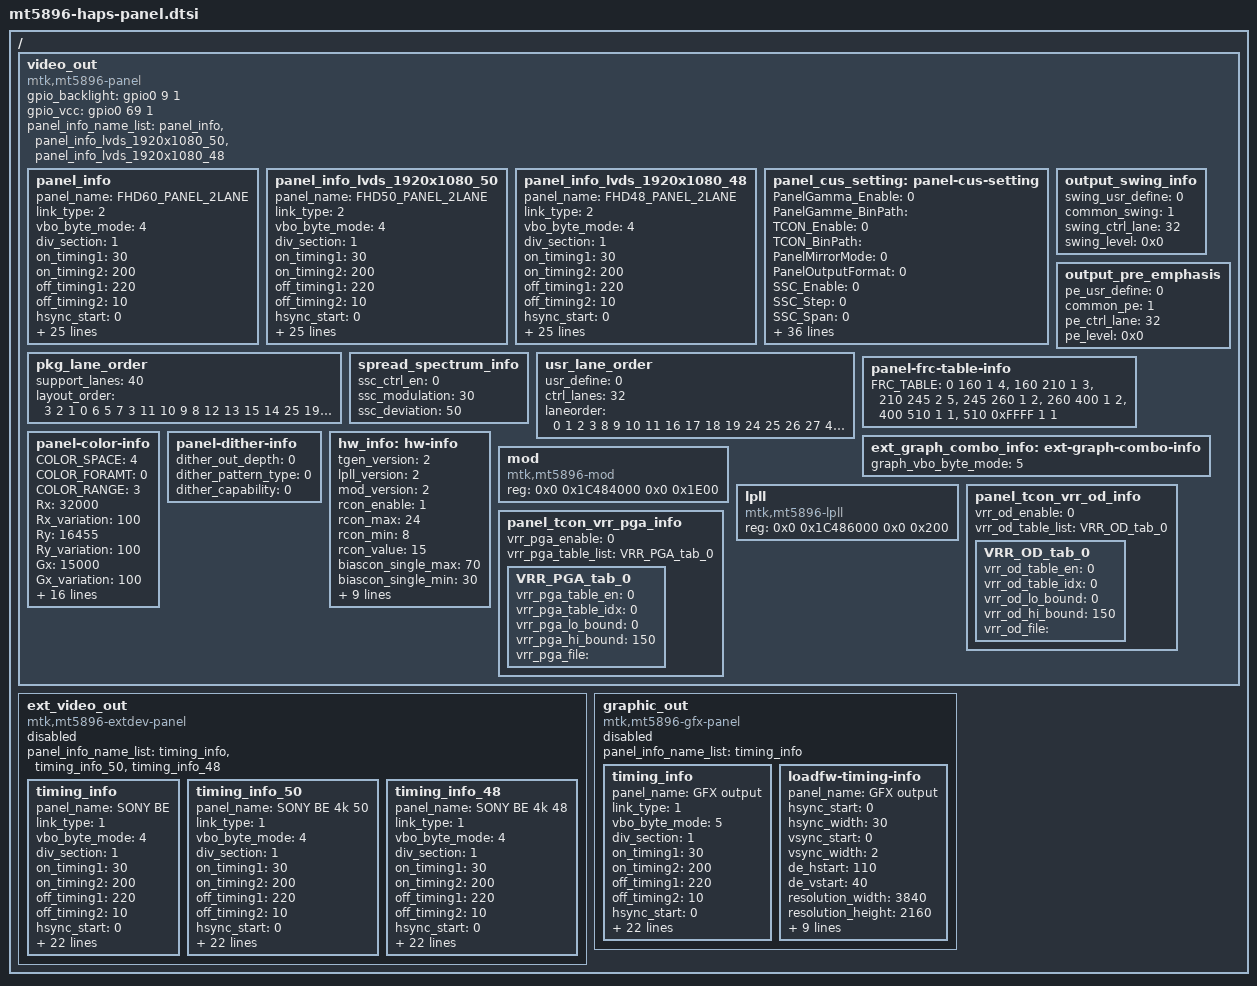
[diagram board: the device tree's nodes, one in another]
// SPDX-License-Identifier: (GPL-2.0 OR BSD-3-Clause)
/*
 * Copyright (c) 2020 MediaTek Inc.
 */

/{

	video_out:video_out {
		compatible = "mtk,mt5896-panel";
		status = "okay";
	#address-cells = <2>;
	#size-cells = <2>;
		gpio_backlight = <&gpio0 9 1>;
		gpio_vcc = <&gpio0 69 1>;
		panel_info_name_list = "panel_info", "panel_info_lvds_1920x1080_50",
		"panel_info_lvds_1920x1080_48";
		panel_info {
			panel_name = "FHD60_PANEL_2LANE";
			link_type = <2>;
			vbo_byte_mode = <4>;
			div_section = <1>;
			on_timing1 = <30>;
			on_timing2 = <200>;
			off_timing1 = <220>;
			off_timing2 = <10>;
			hsync_start = <0>;
			hsync_width = <30>;
			hsync_polarity = <1>;
			vsync_start = <0>;
			vsync_width = <2>;
			vsync_polarity = <1>;
			de_hstart = <110>;
			de_vstart = <98>;
			resolution_width = <1920>;
			resolution_height = <1080>;
			max_h_total = <2300>;
			typ_h_total = <2200>;
			min_h_total = <2100>;
			max_v_total = <1418>;
			typ_v_total = <1125>;
			min_v_total = <1078>;
			max_clk = <160000000>;
			typ_clk = <148500000>;
			min_clk = <140000000>;
			output_format = <0>;
			content_output_format = <0>;
			vrr_en = <0>;
			min_vrr_framerate = <30>;
			max_vrr_framerate = <120>;
			graphic_mixer1_outmode = <0>;
			graphic_mixer2_outmode = <1>;
		};
		panel_info_lvds_1920x1080_50 {
			panel_name = "FHD50_PANEL_2LANE";
			link_type = <2>;
			vbo_byte_mode = <4>;
			div_section = <1>;
			on_timing1 = <30>;
			on_timing2 = <200>;
			off_timing1 = <220>;
			off_timing2 = <10>;
			hsync_start = <0>;
			hsync_width = <30>;
			hsync_polarity = <1>;
			vsync_start = <0>;
			vsync_width = <2>;
			vsync_polarity = <1>;
			de_hstart = <110>;
			de_vstart = <98>;
			resolution_width = <1920>;
			resolution_height = <1080>;
			max_h_total = <2300>;
			typ_h_total = <2200>;
			min_h_total = <2100>;
			max_v_total = <1418>;
			typ_v_total = <1350>;
			min_v_total = <1078>;
			max_clk = <160000000>;
			typ_clk = <148500000>;
			min_clk = <140000000>;
			output_format = <0>;
			content_output_format = <0>;
			vrr_en = <0>;
			min_vrr_framerate = <30>;
			max_vrr_framerate = <120>;
			graphic_mixer1_outmode = <0>;
			graphic_mixer2_outmode = <1>;
		};
panel_info_lvds_1920x1080_48 {
			panel_name = "FHD48_PANEL_2LANE";
			link_type = <2>;
			vbo_byte_mode = <4>;
			div_section = <1>;
			on_timing1 = <30>;
			on_timing2 = <200>;
			off_timing1 = <220>;
			off_timing2 = <10>;
			hsync_start = <0>;
			hsync_width = <30>;
			hsync_polarity = <1>;
			vsync_start = <0>;
			vsync_width = <2>;
			vsync_polarity = <1>;
			de_hstart = <110>;
			de_vstart = <98>;
			resolution_width = <1920>;
			resolution_height = <1080>;
			max_h_total = <2300>;
			typ_h_total = <2200>;
			min_h_total = <2100>;
			max_v_total = <1418>;
			typ_v_total = <1406>;
			min_v_total = <1078>;
			max_clk = <160000000>;
			typ_clk = <148500000>;
			min_clk = <140000000>;
			output_format = <0>;
			content_output_format = <0>;
			vrr_en = <0>;
			min_vrr_framerate = <30>;
			max_vrr_framerate = <120>;
			graphic_mixer1_outmode = <0>;
			graphic_mixer2_outmode = <1>;
		};
	panel_cus_setting:panel-cus-setting {
			PanelGamma_Enable = <0>;
			PanelGamme_BinPath = "";
			TCON_Enable = <0>;
			TCON_BinPath = "";
			PanelMirrorMode = <0>;
			PanelOutputFormat = <0>;
			SSC_Enable = <0>;
			SSC_Step = <0>;
			SSC_Span = <0>;
			OverDrive_Enable = <0>;
			OverDrive_Buf_Addr = <0>;
			OverDrive_Buf_Size = <0>;
			GPIO_Backlight = <0>;
			GPIO_VCC = <0>;
			M_delta = <4>;
			CustomerColorPrimaries = <0>;
			SourceWx = <15635>;
			SourceWy = <16450>;
			VIDEO_GFX_DISPLAY_MODE = <0>;
			OSD_Height = <1920>;
			OSD_Width = <1080>;
			OSD_HsyncStart = <0>;
			OSD_HsyncEnd = <0>;
			OSD_HDEStart = <0>;
			OSD_HDEEnd = <0>;
			OSD_HTotal = <0>;
			OSD_VsyncStart = <0>;
			OSD_VsyncEnd = <0>;
			OSD_VDEStart = <0>;
			OSD_VDEEnd = <0>;
			OSD_VTotal = <0>;

			cus_x_dpi = <0>;
			cus_y_dpi = <0>;

			u32PeriodPWM = <0xFFFF>;
			u32DutyPWM = <0x3FFF>;
			u16DivPWM = <0x00>;
			bPolPWM = <0>;
			u16MaxPWMvalue = <0xFFFF>;
			u16MinPWMvalue = <0x2000>;
			u16PWMPort = <0>;
		graphic_mixer1_outmode = <0>;
		graphic_mixer2_outmode = <1>;
			InchSize = <47>;
			Panel_Name = "MTK_TV_Panel";
			PWM_to_BL_delay = <0>;
		};

	output_swing_info:output_swing_info {
			swing_usr_define = <0>;
			common_swing = <1>;
			swing_ctrl_lane = <32>;
			swing_level = <0x0>;
		};

	output_pre_emphasis:output_pre_emphasis {
			pe_usr_define = <0>;
			common_pe = <1>;
			pe_ctrl_lane = <32>;
			pe_level = <0x0>;
		};

		pkg_lane_order:pkg_lane_order {
			support_lanes = <40>;
			layout_order = < 3  2  1  0  6  5  7  3  11 10  9 8 12 13 15 14
					25 19 16 27 28 17 18 20 29 21 22 23 26 24 30 31
					33 32 34 35 36 39 37 38>;
		};

	spread_spectrum_info:spread_spectrum_info {
			ssc_ctrl_en = <0>;
			ssc_modulation = <30>;
			ssc_deviation = <50>;
		};

		usr_lane_order:usr_lane_order {
			usr_define = <0>;
			ctrl_lanes = <32>;
			laneorder = < 0 1 2 3 8 9 10 11 16 17 18 19 24 25 26 27
					4 5 6 7 12 13 14 15 20 21 22 23 28 29 30 31>;
		};

	panel-frc-table-info {
		FRC_TABLE =
		<0 160 1 4>,
		<160 210 1 3>,
		<210 245 2 5>,
		<245 260 1 2>,
		<260 400 1 2>,
		<400 510 1 1>,
		<510 0xFFFF 1 1>;
	};
		panel-color-info {
			COLOR_SPACE = <4>;
			COLOR_FORAMT = <0>;
			COLOR_RANGE = <3>;
			Rx = <32000>;
		Rx_variation = <100>;
			Ry = <16455>;
		Ry_variation = <100>;
			Gx = <15000>;
		Gx_variation = <100>;
			Gy = <30000>;
		Gy_variation = <100>;
			Bx = <7500>;
		Bx_variation = <100>;
			By = <3000>;
		By_variation = <100>;
			Wx = <15635>;
		Wx_variation = <100>;
			Wy = <16450>;
		Wy_variation = <100>;
			MaxLuminance = <100>;
			MedLuminance = <50>;
			MinLuminance = <500>;
			LinearRGB = <1>;
			HDRPanelNits = <399>;
		DynamicLuminance = <0>;
		};
		panel-dither-info {
			dither_out_depth = <0>;
			dither_pattern_type = <0>;
			dither_capability = <0>;
		};
	hw_info:hw-info {
		  tgen_version = <2>;
		  lpll_version = <2>;
		  mod_version = <2>;
		  rcon_enable = <1>;
		  rcon_max = <24>;
		  rcon_min = <8>;
		  rcon_value = <15>;
		  biascon_single_max = <70>;
		  biascon_single_min = <30>;
		  biascon_single_value = <48>;
		  biascon_double_max = <70>;
		  biascon_double_min = <30>;
		  biascon_double_value = <48>;
		  rint_enable =<0>;
		  rint_max = <0>;
		  rint_min = <0>;
		  rint_value = <0>;
		  pnl_lib_version = <0xFF>;
		};
	ext_graph_combo_info:ext-graph-combo-info {
			graph_vbo_byte_mode = <5>;
		};
	mod: mod{
		compatible = "mtk,mt5896-mod";
		reg = <0x0 0x1C484000 0x0 0x1E00>;
	};
	lpll: lpll{
		compatible = "mtk,mt5896-lpll";
		reg = <0x0 0x1C486000 0x0 0x200>;
	};
		panel_tcon_vrr_od_info:panel_tcon_vrr_od_info { /*VRR OD info*/
			vrr_od_enable = <0>;
			vrr_od_table_list = "VRR_OD_tab_0";
			VRR_OD_tab_0 {
				vrr_od_table_en = <0>;
				vrr_od_table_idx = <0>;
				vrr_od_lo_bound = <0>;
				vrr_od_hi_bound = <150>;
				vrr_od_file = "";
			};
		};
		panel_tcon_vrr_pga_info:panel_tcon_vrr_pga_info { /*VRR PGA info*/
			vrr_pga_enable = <0>;
			vrr_pga_table_list = "VRR_PGA_tab_0";
			VRR_PGA_tab_0 {
				vrr_pga_table_en = <0>;
				vrr_pga_table_idx = <0>;
				vrr_pga_lo_bound = <0>;
				vrr_pga_hi_bound = <150>;
				vrr_pga_file = "";
			};
		};
	};

	ext_video_out: ext_video_out {
	compatible = "mtk,mt5896-extdev-panel";
			status= "disable";
		panel_info_name_list = "timing_info", "timing_info_50",
		"timing_info_48";
		timing_info {
				panel_name = "SONY BE";
				link_type = <1>;
				vbo_byte_mode = <4>;
				div_section = <1>;
				on_timing1 = <30>;
				on_timing2 = <200>;
				off_timing1 = <220>;
				off_timing2 = <10>;
				hsync_start = <0>;
				hsync_width = <30>;
				hsync_polarity = <0>;
				vsync_start = <0>;
				vsync_width = <2>;
				vsync_polarity = <0>;
				de_hstart = <110>;
				de_vstart = <40>;
				resolution_width = <3840>;
				resolution_height = <2160>;
				max_h_total = <4500>;
				typ_h_total = <4400>;
				min_h_total = <4300>;
				max_v_total = <2350>;
				typ_v_total = <2250>;
				min_v_total = <2150>;
				max_clk = <620000000>;
				typ_clk = <594000000>;
				min_clk = <560000000>;
				output_format = <1>;
				content_output_format = <1>;
			graphic_mixer1_outmode = <0>;
			graphic_mixer2_outmode = <1>;
			};
timing_info_50 {
			panel_name = "SONY BE 4k 50";
			link_type = <1>;
			vbo_byte_mode = <4>;
			div_section = <1>;
			on_timing1 = <30>;
			on_timing2 = <200>;
			off_timing1 = <220>;
			off_timing2 = <10>;
			hsync_start = <0>;
			hsync_width = <30>;
			hsync_polarity = <1>;
			vsync_start = <0>;
			vsync_width = <2>;
			vsync_polarity = <1>;
			de_hstart = <112>;
			de_vstart = <40>;
			resolution_width = <3840>;
			resolution_height = <2160>;
			max_h_total = <4500>;
			typ_h_total = <4400>;
			min_h_total = <4300>;
			max_v_total = <2800>;
			typ_v_total = <2700>;
			min_v_total = <2600>;
			max_clk = <620000000>;
			typ_clk = <594000000>;
			min_clk = <560000000>;
			output_format = <0>;
			content_output_format = <0>;
			graphic_mixer1_outmode = <0>;
			graphic_mixer2_outmode = <1>;
		};
		timing_info_48 {
			panel_name = "SONY BE 4k 48";
			link_type = <1>;
			vbo_byte_mode = <4>;
			div_section = <1>;
			on_timing1 = <30>;
			on_timing2 = <200>;
			off_timing1 = <220>;
			off_timing2 = <10>;
			hsync_start = <0>;
			hsync_width = <30>;
			hsync_polarity = <1>;
			vsync_start = <0>;
			vsync_width = <2>;
			vsync_polarity = <1>;
			de_hstart = <112>;
			de_vstart = <40>;
			resolution_width = <3840>;
			resolution_height = <2160>;
			max_h_total = <4500>;
			typ_h_total = <4400>;
			min_h_total = <4300>;
			max_v_total = <2912>;
			typ_v_total = <2812>;
			min_v_total = <2712>;
			max_clk = <620000000>;
			typ_clk = <594000000>;
			min_clk = <560000000>;
			output_format = <0>;
			content_output_format = <0>;
			graphic_mixer1_outmode = <0>;
			graphic_mixer2_outmode = <1>;
		};
	};

	graphic_out:graphic_out {
			compatible = "mtk,mt5896-gfx-panel";
			status = "disable";
	panel_info_name_list = "timing_info";
	timing_info {
				panel_name = "GFX output";
				link_type = <1>;
				vbo_byte_mode = <5>;
				div_section = <1>;
				on_timing1 = <30>;
				on_timing2 = <200>;
				off_timing1 = <220>;
				off_timing2 = <10>;
				hsync_start = <0>;
				hsync_width = <30>;
				hsync_polarity = <1>;
				vsync_start = <0>;
				vsync_width = <2>;
				vsync_polarity = <1>;
				de_hstart = <110>;
				de_vstart = <40>;
				resolution_width = <3840>;
				resolution_height = <2160>;
				max_h_total = <4500>;
				typ_h_total = <4400>;
				min_h_total = <4300>;
				max_v_total = <2350>;
				typ_v_total = <2250>;
				min_v_total = <2150>;
				max_clk = <620000000>;
				typ_clk = <594000000>;
				min_clk = <560000000>;
				output_format = <8>;
				content_output_format = <4>;
		graphic_mixer1_outmode = <0>;
		graphic_mixer2_outmode = <1>;
			};
			loadfw-timing-info {
				panel_name = "GFX output";
				hsync_start = <0>;
				hsync_width = <30>;
				vsync_start = <0>;
				vsync_width = <2>;
				de_hstart = <110>;
				de_vstart = <40>;
				resolution_width = <3840>;
				resolution_height = <2160>;
				max_h_total = <4500>;
				typ_h_total = <4400>;
				min_h_total = <4300>;
				max_v_total = <2350>;
				typ_v_total = <2250>;
				min_v_total = <2150>;
				max_clk = <620000000>;
				typ_clk = <594000000>;
				min_clk = <560000000>;
			};
	};
};
